# STM32U083xx register map
File version: 1.0
Registers are 32-bit, read-write, reset 0x0 unless marked. A register's access mark holds for its fields unless they carry their own. Offsets are from the block's base; [hi:lo] are bit positions; {n}, {i} and the like mark numbered series.

## RCC — Reset and Clock Control
Base 0x40021000
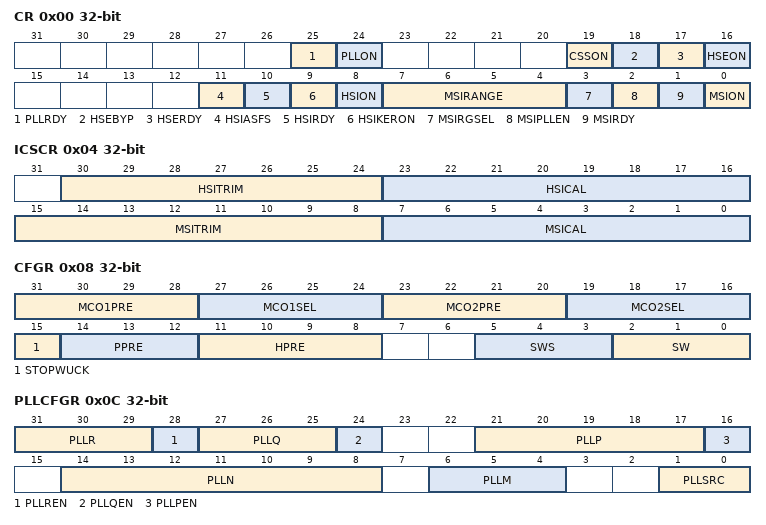
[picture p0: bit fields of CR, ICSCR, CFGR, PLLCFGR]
0x00 CR — RCC Clock Sources Control Register
  [25] PLLRDY — System PLL clock ready
  [24] PLLON — System PLL clock enable
  [19] CSSON — HSE Clock Security System enable
  [18] HSEBYP — External High Speed oscillator (HSE) clock bypass
  [17] HSERDY — External High Speed oscillator (HSE) clock ready
  [16] HSEON — External High Speed oscillator (HSE) clock enable
  [11] HSIASFS — HSI16 Automatic Start from Stop
  [10] HSIRDY — Internal High Speed oscillator (HSI16) clock ready flag
  [9] HSIKERON — Internal High Speed oscillator (HSI16) clock enable for some IPs Kernel
  [8] HSION — Internal High Speed oscillator (HSI16) clock enable
  [7:4] MSIRANGE — Internal Multi Speed oscillator (MSI) clock Range
    0=MSI = 100 KHz; 1=MSI = 200 KHz; 2=MSI = 400 KHz; 3=MSI = 800 KHz; 4=MSI = 1 MHz; 5=MSI = 2 MHz; 6=MSI = 4 MHz; 7=MSI = 8 MHz; 8=MSI = 16 MHz; 9=MSI = 24 MHz; 10=MSI = 32 MHz; 11=MSI = 48 MHz
  [3] MSIRGSEL — Internal Multi Speed oscillator (MSI) range selection
  [2] MSIPLLEN — Internal Multi Speed oscillator (MSI) PLL enable
  [1] MSIRDY — Internal Multi Speed oscillator (MSI) clock ready flag
  [0] MSION — Internal Multi Speed oscillator (MSI) clock enable
0x04 ICSCR — RCC Internal Clock Sources Calibration Register
  [30:24] HSITRIM — HSITRIM[6:0] bits
  [23:16] HSICAL — HSICAL[7:0] bits
  [15:8] MSITRIM — MSITRIM[7:0] bits
  [7:0] MSICAL — MSICAL[7:0] bits
0x08 CFGR — RCC Regulated Domain Clocks Configuration Register
  [31:28] MCO1PRE — MCO1 prescaler [3:0]
  [27:24] MCO1SEL — MCO1SEL [3:0] bits (Clock output selection)
  [23:20] MCO2PRE — MCO1 prescaler [3:0]
  [19:16] MCO2SEL — MCO2SEL [3:0] bits (Clock output selection)
  [15] STOPWUCK — Wake Up from stop and CSS backup clock selection
    0=MSI (MSI selection after wake-up from STOP); 1=HSI (HSI selection after wake-up from STOP)
  [14:12] PPRE — PRE1[2:0] bits (APB prescaler)
    0=DIV_1 (APB not divided); 4=DIV_2 (APB divided by 2); 5=DIV_4 (APB divided by 4); 6=DIV_8 (APB divided by 8); 7=DIV_16 (APB divided by 16)
  [11:8] HPRE — HPRE[3:0] bits (AHB prescaler)
    0=DIV_1 (SYSCLK not divided); 8=DIV_2 (SYSCLK divided by 2); 9=DIV_4 (SYSCLK divided by 4); 10=DIV_8 (SYSCLK divided by 8); 11=DIV_16 (SYSCLK divided by 16); 12=DIV_64 (SYSCLK divided by 64); 13=DIV_128 (SYSCLK divided by 128); 14=DIV_256 (SYSCLK divided by 256); 15=DIV_512 (SYSCLK divided by 512)
  [5:3] SWS — SWS[2:0] bits (System Clock Switch Status)
    0=MSI (MSI used as system clock); 1=HSI (HSI used as system clock); 2=HSE (HSE used as system clock); 3=PLL (PLL used as system clock); 4=LSI (LSI used as system clock); 5=LSE (LSE used as system clock)
  [2:0] SW — SW[2:0] bits (System clock Switch)
    0=MSI (MSI selection as system clock); 1=HSI (HSI selection as system clock); 2=HSE (HSE selection as system clock); 3=PLL (PLL selection as system clock); 4=LSI (LSI selection as system clock); 5=LSE (LSE selection as system clock)
0x0C PLLCFGR — RCC system PLL configuration register
  [31:29] PLLR
    1=DIV_2 (Main PLL division factor for PLLCLK (system clock) by 2); 3=DIV_4 (Main PLL division factor for PLLCLK (system clock) by 4); 5=DIV_6 (Main PLL division factor for PLLCLK (system clock) by 6); 7=DIV_8 (Main PLL division factor for PLLCLK (system clock) by 8)
  [28] PLLREN
  [27:25] PLLQ
    1=DIV_2 (Main PLL division factor for PLLQ output by 2); 3=DIV_4 (Main PLL division factor for PLLQ output by 4); 5=DIV_6 (Main PLL division factor for PLLQ output by 6); 7=DIV_8 (Main PLL division factor for PLLQ output by 8)
  [24] PLLQEN
  [21:17] PLLP
    {v}=DIV_{v+1} (Main PLL division factor for PLLP output by {v+1}) (v=1..30)
  [16] PLLPEN
  [14:8] PLLN
  [6:4] PLLM
    {v}=DIV_{v+1} (Main PLL division factor for PLLM input by {v+1}) (v=0..7)
  [1:0] PLLSRC
    0=NONE (No clock selected as main PLL entry clock source); 1=MSI (MSI clock selected as main PLL entry clock source); 2=HSI (HSI16 clock selected as main PLL entry clock source); 3=HSE (HSE clock selected as main PLL entry clock source)
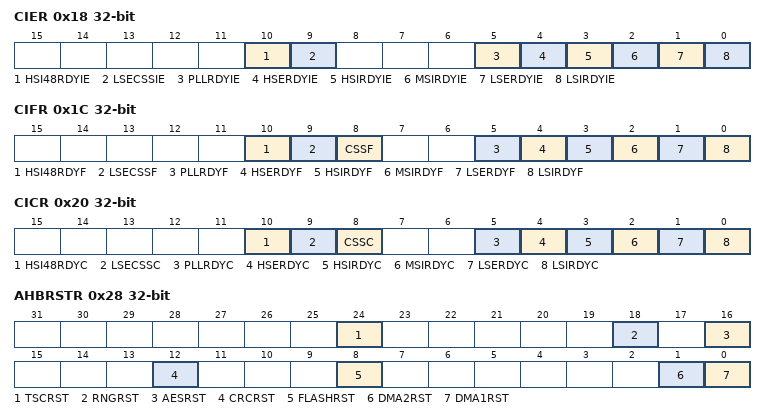
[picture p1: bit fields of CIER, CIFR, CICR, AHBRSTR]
0x18 CIER — RCC Clock Interrupt Enable Register
  [10] HSI48RDYIE, [9] LSECSSIE, [5] PLLRDYIE, [4] HSERDYIE, [3] HSIRDYIE, [2] MSIRDYIE, [1] LSERDYIE, [0] LSIRDYIE
0x1C CIFR — RCC Clock Interrupt Flag Register
  [10] HSI48RDYF, [9] LSECSSF, [8] CSSF, [5] PLLRDYF, [4] HSERDYF, [3] HSIRDYF, [2] MSIRDYF, [1] LSERDYF, [0] LSIRDYF
0x20 CICR — RCC Clock Interrupt Clear Register
  [10] HSI48RDYC, [9] LSECSSC, [8] CSSC, [5] PLLRDYC, [4] HSERDYC, [3] HSIRDYC, [2] MSIRDYC, [1] LSERDYC, [0] LSIRDYC
0x28 AHBRSTR — RCC AHB peripheral reset register
  [24] TSCRST, [18] RNGRST, [16] AESRST, [12] CRCRST, [8] FLASHRST, [1] DMA2RST, [0] DMA1RST
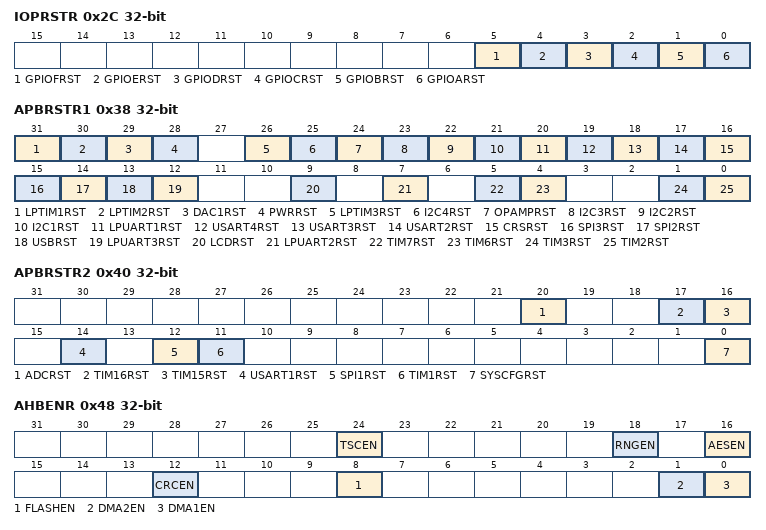
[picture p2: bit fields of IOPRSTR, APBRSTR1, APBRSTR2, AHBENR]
0x2C IOPRSTR — RCC AHB2 peripheral reset register
  [5] GPIOFRST, [4] GPIOERST, [3] GPIODRST, [2] GPIOCRST, [1] GPIOBRST, [0] GPIOARST
0x38 APBRSTR1 — RCC APB1 peripheral reset register
  [31] LPTIM1RST, [30] LPTIM2RST, [29] DAC1RST, [28] PWRRST, [26] LPTIM3RST, [25] I2C4RST, [24] OPAMPRST, [23] I2C3RST, [22] I2C2RST, [21] I2C1RST, [20] LPUART1RST, [19] USART4RST, [18] USART3RST, [17] USART2RST, [16] CRSRST, [15] SPI3RST, [14] SPI2RST, [13] USBRST, [12] LPUART3RST, [9] LCDRST, [7] LPUART2RST, [5] TIM7RST, [4] TIM6RST, [1] TIM3RST, [0] TIM2RST
0x40 APBRSTR2 — RCC APB2 peripheral reset register
  [20] ADCRST, [17] TIM16RST, [16] TIM15RST, [14] USART1RST, [12] SPI1RST, [11] TIM1RST, [0] SYSCFGRST
0x48 AHBENR — RCC AHB peripheral clocks enable register
  [24] TSCEN, [18] RNGEN, [16] AESEN, [12] CRCEN, [8] FLASHEN, [1] DMA2EN, [0] DMA1EN
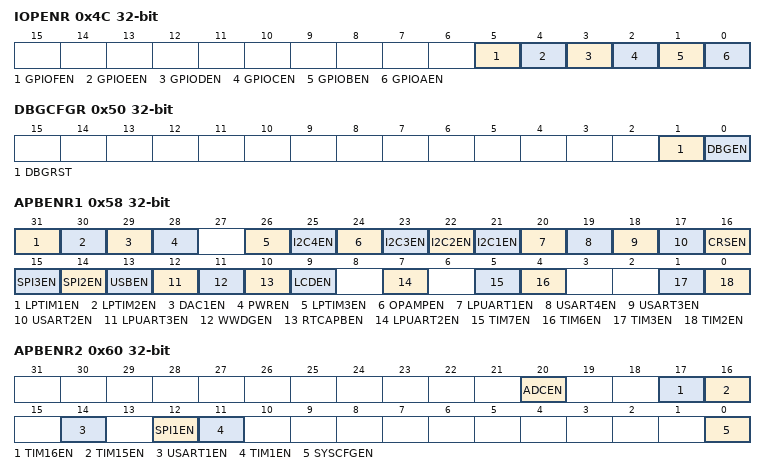
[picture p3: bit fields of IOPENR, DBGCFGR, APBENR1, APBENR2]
0x4C IOPENR — RCC IO port enable register
  [5] GPIOFEN, [4] GPIOEEN, [3] GPIODEN, [2] GPIOCEN, [1] GPIOBEN, [0] GPIOAEN
0x50 DBGCFGR — RCC DBGCFGR control register
  [1] DBGRST, [0] DBGEN
0x58 APBENR1 — RCC APB1 peripherals clock enable register
  [31] LPTIM1EN, [30] LPTIM2EN, [29] DAC1EN, [28] PWREN, [26] LPTIM3EN, [25] I2C4EN, [24] OPAMPEN, [23] I2C3EN, [22] I2C2EN, [21] I2C1EN, [20] LPUART1EN, [19] USART4EN, [18] USART3EN, [17] USART2EN, [16] CRSEN, [15] SPI3EN, [14] SPI2EN, [13] USBEN, [12] LPUART3EN, [11] WWDGEN, [10] RTCAPBEN, [9] LCDEN, [7] LPUART2EN, [5] TIM7EN, [4] TIM6EN, [1] TIM3EN, [0] TIM2EN
0x60 APBENR2 — RCC APB2 peripherals clock enable register
  [20] ADCEN, [17] TIM16EN, [16] TIM15EN, [14] USART1EN, [12] SPI1EN, [11] TIM1EN, [0] SYSCFGEN
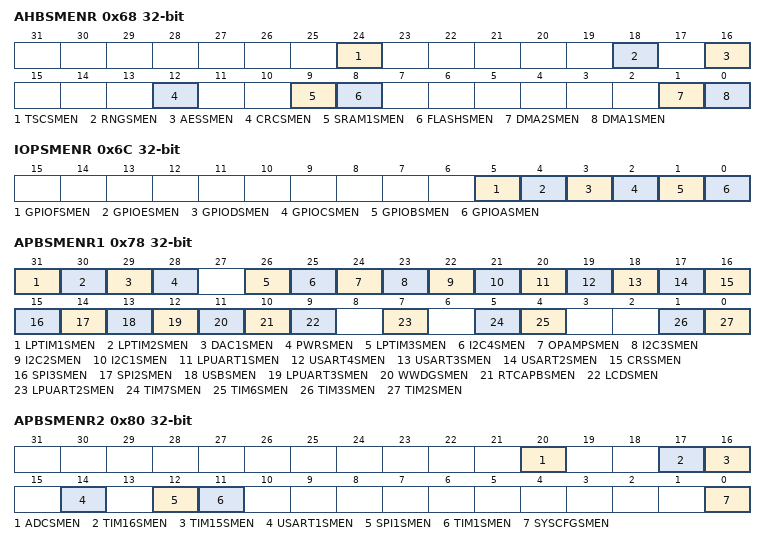
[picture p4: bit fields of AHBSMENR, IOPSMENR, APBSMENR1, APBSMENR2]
0x68 AHBSMENR — RCC AHB peripheral clocks enable in sleep mode register
  [24] TSCSMEN, [18] RNGSMEN, [16] AESSMEN, [12] CRCSMEN, [9] SRAM1SMEN, [8] FLASHSMEN, [1] DMA2SMEN, [0] DMA1SMEN
0x6C IOPSMENR — RCC IO port peripheral clocks enable in sleep mode register
  [5] GPIOFSMEN, [4] GPIOESMEN, [3] GPIODSMEN, [2] GPIOCSMEN, [1] GPIOBSMEN, [0] GPIOASMEN
0x78 APBSMENR1 — RCC APB1 peripheral clocks enable in sleep mode register
  [31] LPTIM1SMEN, [30] LPTIM2SMEN, [29] DAC1SMEN, [28] PWRSMEN, [26] LPTIM3SMEN, [25] I2C4SMEN, [24] OPAMPSMEN, [23] I2C3SMEN, [22] I2C2SMEN, [21] I2C1SMEN, [20] LPUART1SMEN, [19] USART4SMEN, [18] USART3SMEN, [17] USART2SMEN, [16] CRSSMEN, [15] SPI3SMEN, [14] SPI2SMEN, [13] USBSMEN, [12] LPUART3SMEN, [11] WWDGSMEN, [10] RTCAPBSMEN, [9] LCDSMEN, [7] LPUART2SMEN, [5] TIM7SMEN, [4] TIM6SMEN, [1] TIM3SMEN, [0] TIM2SMEN
0x80 APBSMENR2 — RCC APB2 peripheral clocks enable in sleep mode register
  [20] ADCSMEN, [17] TIM16SMEN, [16] TIM15SMEN, [14] USART1SMEN, [12] SPI1SMEN, [11] TIM1SMEN, [0] SYSCFGSMEN
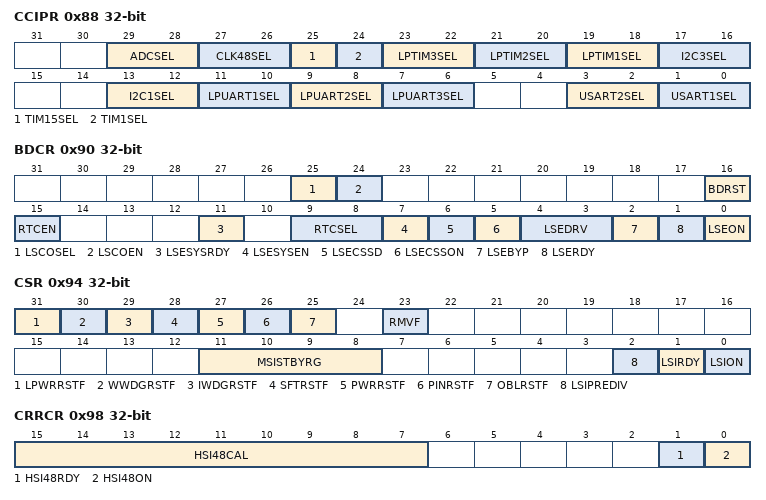
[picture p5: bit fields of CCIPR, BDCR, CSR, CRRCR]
0x88 CCIPR — RCC Peripherals Independent Clocks Configuration Register
  [29:28] ADCSEL
    3=NONE (No clock used as ADC clock source); 1=PLLP (PLL P clock used as ADC clock source); 2=HSI (HSI clock used as ADC clock source); 0=SYSCLK (SYSCLK clock used as ADC clock source)
  [27:26] CLK48SEL
    0=NONE (No clock used as RNG clock source); 3=HSI48 (HSI48 clock used as RNG clock source); 2=PLLQ (PLL clock used as RNG clock source); 1=MSI (MSI clock used as RNG clock source)
  [25] TIM15SEL
  [24] TIM1SEL
  [23:22] LPTIM3SEL
  [21:20] LPTIM2SEL
  [19:18] LPTIM1SEL
  [17:16] I2C3SEL
  [13:12] I2C1SEL
  [11:10] LPUART1SEL
  [9:8] LPUART2SEL
  [7:6] LPUART3SEL
  [3:2] USART2SEL
  [1:0] USART1SEL
0x90 BDCR — RCC backup domain control register
  [25] LSCOSEL
    0=LSI (LSI selection for low speed clock); 1=LSE (LSE selection for low speed clock)
  [24] LSCOEN
  [16] BDRST
  [15] RTCEN
  [11] LSESYSRDY
  [9:8] RTCSEL
    0=NONE (No clock used as RTC clock); 1=LSE (LSE oscillator clock used as RTC clock); 2=LSI (LSI oscillator clock used as RTC clock); 3=HSE_DIV32 (HSE oscillator clock divided by 32 used as RTC clock)
  [7] LSESYSEN
  [6] LSECSSD
  [5] LSECSSON
  [4:3] LSEDRV
    0=LOW (Xtal mode lower driving capability); 1=MEDIUMLOW (Xtal mode medium low driving capability); 2=MEDIUMHIGH (Xtal mode medium high driving capability); 3=HIGH (Xtal mode higher driving capability)
  [2] LSEBYP
  [1] LSERDY
  [0] LSEON
0x94 CSR — RCC clock control & status register
  [31] LPWRRSTF
  [30] WWDGRSTF
  [29] IWDGRSTF
  [28] SFTRSTF
  [27] PWRRSTF
  [26] PINRSTF
  [25] OBLRSTF
  [23] RMVF
  [11:8] MSISTBYRG
    4=MSISRANGE_4 (MSI = 1 MHz); 5=MSISRANGE_5 (MSI = 2 MHz); 6=MSISRANGE_6 (MSI = 4 MHz); 7=MSISRANGE_7 (MSI = 8 MHz)
  [2] LSIPREDIV
    0=DIV_1 (LSI divided by 1); 1=DIV_128 (LSI divided by 128)
  [1] LSIRDY
  [0] LSION
0x98 CRRCR — RCC clock recovery RC register
  [15:7] HSI48CAL — RC48CAL[8:0] bits
  [1] HSI48RDY — System HSI48 clock ready
  [0] HSI48ON — System HSI48 clock enable
